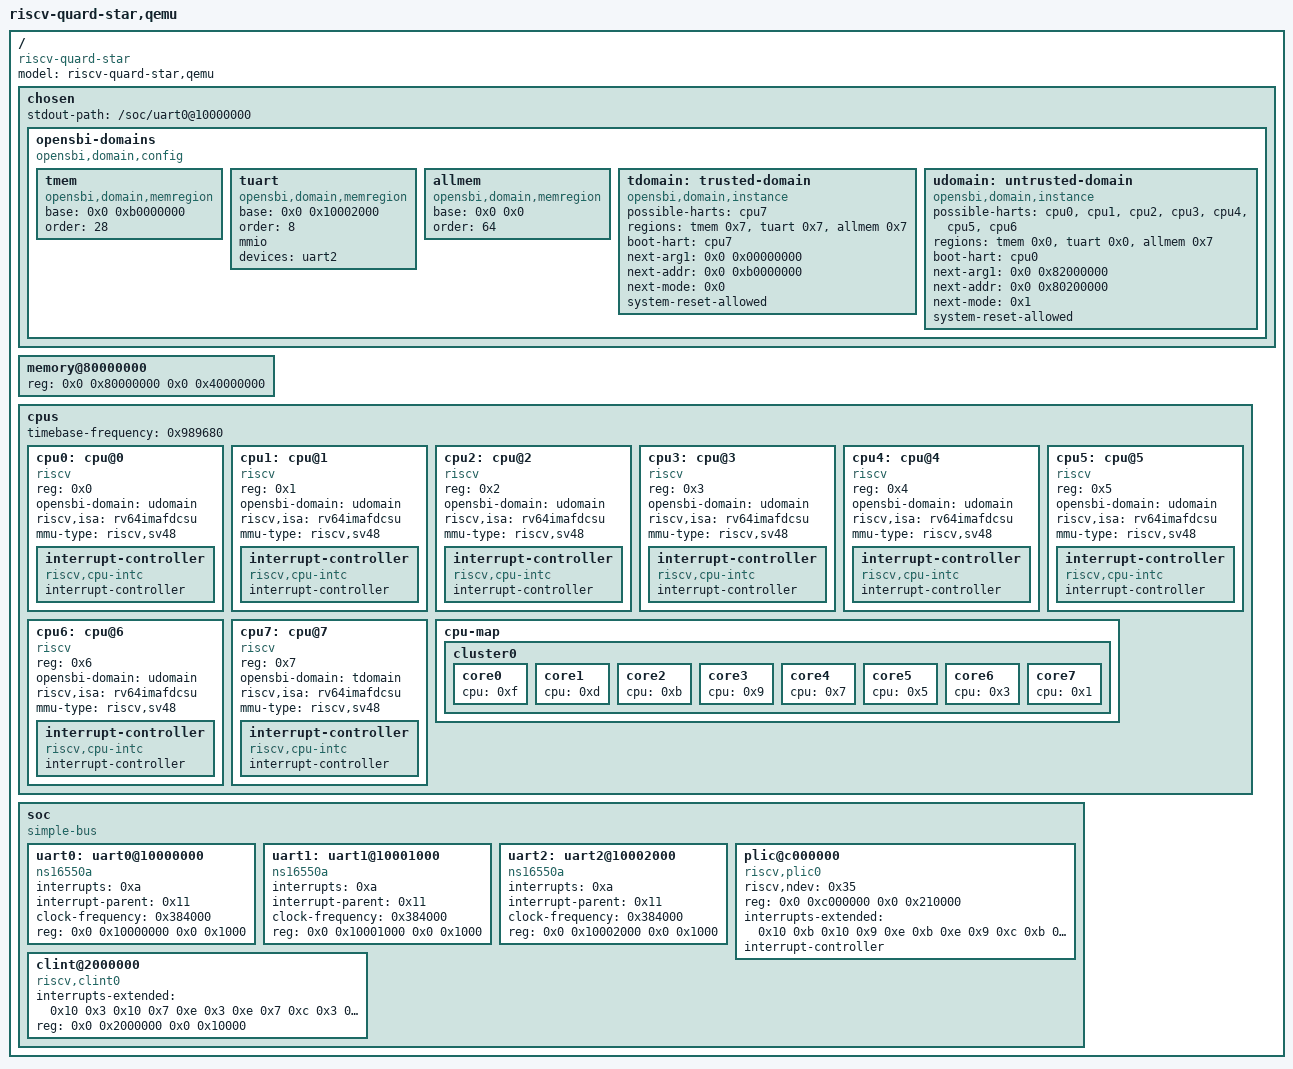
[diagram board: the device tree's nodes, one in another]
/dts-v1/;

/ {
	#address-cells = <0x2>;
	#size-cells = <0x2>;
	compatible = "riscv-quard-star";
	model = "riscv-quard-star,qemu";

	chosen {
		stdout-path = "/soc/uart0@10000000";

		opensbi-domains {  /* 定义opensbi-domains描述节点 */
		    compatible = "opensbi,domain,config"; /* 节点名称 */

            tmem: tmem {   /* 定义内存节点 */
                compatible = "opensbi,domain,memregion";  /* 节点名称 */
                base = <0x0 0xb0000000>; /* 起始地址注意64位地址哦 */
                order = <28>; /* 内存大小即size=2^28 */
            };

            tuart: tuart {  /* 定义mmio节点 */
                compatible = "opensbi,domain,memregion";  /* 节点名称 */
                base = <0x0 0x10002000>; /* 起始地址 */
                order = <8>; /* size=2^8 */
                mmio;  /* mmio属性 */
                devices = <&uart2>; /* 关联到设备节点上 */
            };

		    allmem: allmem { /* 定义内存节点，这个节点保护所有地址 */
		        compatible = "opensbi,domain,memregion";
		        base = <0x0 0x0>;
		        order = <64>;
		    };

            tdomain: trusted-domain { /* 定义domian节点 */
                compatible = "opensbi,domain,instance";  /* 节点名称 */
                possible-harts = <&cpu7>; /* dumian中允许使用的cpu core */
                regions = <&tmem 0x7>, <&tuart 0x7>, <&allmem 0x7>;/* 各个内存/mmio区域的权限，3bit读写运行权限 0x7拥有全部权限 */
                boot-hart = <&cpu7>; /* domian中用于boot的core */
                next-arg1 = <0x0 0x00000000>; /* 下级程序的参数 */
		        next-addr = <0x0 0xb0000000>; /* 下级程序的起始地址 */
		        next-mode = <0x0>; /* 下级程序的允许模式 0为U模式，1为S模式 */
                system-reset-allowed; /* 允许复位 */
            };

		    udomain: untrusted-domain {
		        compatible = "opensbi,domain,instance";
		        possible-harts = <&cpu0 &cpu1 &cpu2 &cpu3 &cpu4 &cpu5 &cpu6>;
		        regions = <&tmem 0x0>, <&tuart 0x0>, <&allmem 0x7>;
				boot-hart = <&cpu0>;
    			next-arg1 = <0x0 0x82000000>; /* 这两个地址之所以改为这个原因是因为默认的riscv64_smode_defconfig配置uboot使用了这两个地址，我们先使用默认配置跑起来uboot，后续会重新规划内存分配 */
    			next-addr = <0x0 0x80200000>; 
		        next-mode = <0x1>;
		        system-reset-allowed;
		    };
		};
	};

	memory@80000000 {
		device_type = "memory";
		reg = <0x0 0x80000000 0x0 0x40000000>;
	};

	cpus {
		#address-cells = <0x1>;
		#size-cells = <0x0>;
		timebase-frequency = <0x989680>;

		cpu0: cpu@0 {
			phandle = <0xf>;
			device_type = "cpu";
			reg = <0x0>;
			status = "okay";
			compatible = "riscv";
			opensbi-domain = <&udomain>;
			riscv,isa = "rv64imafdcsu";
			mmu-type = "riscv,sv48";

			interrupt-controller {
				#interrupt-cells = <0x1>;
				interrupt-controller;
				compatible = "riscv,cpu-intc";
				phandle = <0x10>;
			};
		};

		cpu1: cpu@1 {
			phandle = <0xd>;
			device_type = "cpu";
			reg = <0x1>;
			status = "okay";
			compatible = "riscv";
			opensbi-domain = <&udomain>;
			riscv,isa = "rv64imafdcsu";
			mmu-type = "riscv,sv48";

			interrupt-controller {
				#interrupt-cells = <0x1>;
				interrupt-controller;
				compatible = "riscv,cpu-intc";
				phandle = <0xe>;
			};
		};

		cpu2: cpu@2 {
			phandle = <0xb>;
			device_type = "cpu";
			reg = <0x2>;
			status = "okay";
			compatible = "riscv";
			opensbi-domain = <&udomain>;
			riscv,isa = "rv64imafdcsu";
			mmu-type = "riscv,sv48";

			interrupt-controller {
				#interrupt-cells = <0x1>;
				interrupt-controller;
				compatible = "riscv,cpu-intc";
				phandle = <0xc>;
			};
		};

		cpu3: cpu@3 {
			phandle = <0x9>;
			device_type = "cpu";
			reg = <0x3>;
			status = "okay";
			compatible = "riscv";
			opensbi-domain = <&udomain>;
			riscv,isa = "rv64imafdcsu";
			mmu-type = "riscv,sv48";

			interrupt-controller {
				#interrupt-cells = <0x1>;
				interrupt-controller;
				compatible = "riscv,cpu-intc";
				phandle = <0xa>;
			};
		};

		cpu4: cpu@4 {
			phandle = <0x7>;
			device_type = "cpu";
			reg = <0x4>;
			status = "okay";
			compatible = "riscv";
			opensbi-domain = <&udomain>;
			riscv,isa = "rv64imafdcsu";
			mmu-type = "riscv,sv48";

			interrupt-controller {
				#interrupt-cells = <0x1>;
				interrupt-controller;
				compatible = "riscv,cpu-intc";
				phandle = <0x8>;
			};
		};

		cpu5: cpu@5 {
			phandle = <0x5>;
			device_type = "cpu";
			reg = <0x5>;
			status = "okay";
			compatible = "riscv";
			opensbi-domain = <&udomain>;
			riscv,isa = "rv64imafdcsu";
			mmu-type = "riscv,sv48";

			interrupt-controller {
				#interrupt-cells = <0x1>;
				interrupt-controller;
				compatible = "riscv,cpu-intc";
				phandle = <0x6>;
			};
		};

		cpu6: cpu@6 {
			phandle = <0x3>;
			device_type = "cpu";
			reg = <0x6>;
			status = "okay";
			compatible = "riscv";
			opensbi-domain = <&udomain>;
			riscv,isa = "rv64imafdcsu";
			mmu-type = "riscv,sv48";

			interrupt-controller {
				#interrupt-cells = <0x1>;
				interrupt-controller;
				compatible = "riscv,cpu-intc";
				phandle = <0x4>;
			};
		};

		cpu7: cpu@7 {
			phandle = <0x1>;
			device_type = "cpu";
			reg = <0x7>;
			status = "okay";
			compatible = "riscv";
			opensbi-domain = <&tdomain>;
			riscv,isa = "rv64imafdcsu";
			mmu-type = "riscv,sv48";

			interrupt-controller {
				#interrupt-cells = <0x1>;
				interrupt-controller;
				compatible = "riscv,cpu-intc";
				phandle = <0x2>;
			};
		};

		cpu-map {

			cluster0 {

				core0 {
					cpu = <0xf>;
				};

				core1 {
					cpu = <0xd>;
				};

				core2 {
					cpu = <0xb>;
				};

				core3 {
					cpu = <0x9>;
				};

				core4 {
					cpu = <0x7>;
				};

				core5 {
					cpu = <0x5>;
				};

				core6 {
					cpu = <0x3>;
				};

				core7 {
					cpu = <0x1>;
				};
			};
		};
	};

	soc {
		#address-cells = <0x2>;
		#size-cells = <0x2>;
		compatible = "simple-bus";
		ranges;

		uart0: uart0@10000000 {
			interrupts = <0xa>;
			interrupt-parent = <0x11>;
			clock-frequency = <0x384000>;
			reg = <0x0 0x10000000 0x0 0x1000>;
			compatible = "ns16550a";
		};

		uart1: uart1@10001000 {
			interrupts = <0xa>;
			interrupt-parent = <0x11>;
			clock-frequency = <0x384000>;
			reg = <0x0 0x10001000 0x0 0x1000>;
			compatible = "ns16550a";
		};

        uart2: uart2@10002000 {
			interrupts = <0xa>;
			interrupt-parent = <0x11>;
			clock-frequency = <0x384000>;
			reg = <0x0 0x10002000 0x0 0x1000>;
			compatible = "ns16550a";
		};

		plic@c000000 {
			phandle = <0x11>;
			riscv,ndev = <0x35>;
			reg = <0x0 0xc000000 0x0 0x210000>;
			interrupts-extended = <0x10 0xb 0x10 0x9 0xe 0xb 0xe 0x9 0xc 0xb 0xc 0x9 0xa 0xb 0xa 0x9 0x8 0xb 0x8 0x9 0x6 0xb 0x6 0x9 0x4 0xb 0x4 0x9 0x2 0xb 0x2 0x9>;
			interrupt-controller;
			compatible = "riscv,plic0";
			#interrupt-cells = <0x1>;
			#address-cells = <0x0>;
		};

		clint@2000000 {
			interrupts-extended = <0x10 0x3 0x10 0x7 0xe 0x3 0xe 0x7 0xc 0x3 0xc 0x7 0xa 0x3 0xa 0x7 0x8 0x3 0x8 0x7 0x6 0x3 0x6 0x7 0x4 0x3 0x4 0x7 0x2 0x3 0x2 0x7>;
			reg = <0x0 0x2000000 0x0 0x10000>;
			compatible = "riscv,clint0";
		};
	};
};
